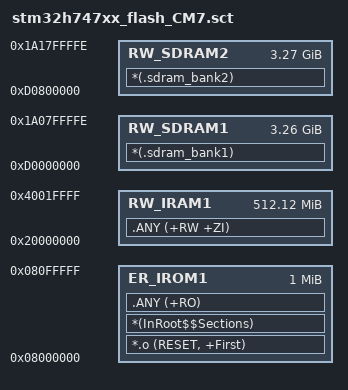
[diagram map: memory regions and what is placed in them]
; *************************************************************
; *** Scatter-Loading Description File generated by uVision ***
; *************************************************************

LR_IROM1 0x08000000 0x00100000 {    ; load region size_region
  ER_IROM1 0x08000000 0x00100000 {  ; load address = execution address
   *.o (RESET, +First)
   *(InRoot$$Sections)
   .ANY (+RO)
  }
  RW_IRAM1 0x20000000 0x20020000 {  ; RW data
   .ANY (+RW +ZI)
  }
  RW_SDRAM1 0xD0000000 0xD07FFFFF {  ; RW data
    *(.sdram_bank1)
  }
  RW_SDRAM2 0xD0800000 0xD0FFFFFF {  ; RW data
    *(.sdram_bank2)
  }
}
